# TLSR826X register map
File version: 0.1
Auto-generated SVD for Telink TLSR826X
Registers are 8-bit, access not given, no defined reset value unless marked. A register's access mark holds for its fields unless they carry their own. Offsets are from the block's base; lines under a group give offsets from that group; [hi:lo] are bit positions; {n}, {i} and the like mark numbered series; 'fields as' and 'values as' point back to an identical list; <NAME> marks a mode.

## Memory map
0x00800000 SECONDARY_I2C — Auto-generated from section 'secondary i2c'
0x00800008 SECONDARY_SPI — Auto-generated from section 'secondary spi'
0x0080000C MASTER_SPI — Auto-generated from section 'master spi'
0x00800010 OTP — Auto-generated from section 'otp'
0x00800028 ADC — Auto-generated from section 'adc'
0x00800056 AUDIO — Auto-generated from section 'audio'
0x00800060 SYS — Auto-generated from section 'sys'
0x00800074 DEV_ID — Auto-generated from section 'dev_id'
0x00800080 MAC — Auto-generated from section 'mac'
0x008000B0 SWIRE — Auto-generated from section 'swire'
0x00800500 DMA_MAC — Auto-generated from section 'dma mac'
0x00800580 GPIO — Auto-generated from section 'gpio'
0x00800620 TIMER — Auto-generated from section 'timer'
0x00800640 INTERRUPT — Auto-generated from section 'interrupt'
0x00800780 PWM — Auto-generated from section 'PWM'
0x00800B00 DFIFO — Auto-generated from section 'dfifo'

## SECONDARY_I2C — Auto-generated from section 'secondary i2c'
Base 0x00800000
0x00 I2C_SET 32-bit — Auto-generated from i2c_set; aliases: I2C_SPEED
0x01 I2C_ID — Auto-generated from i2c_id
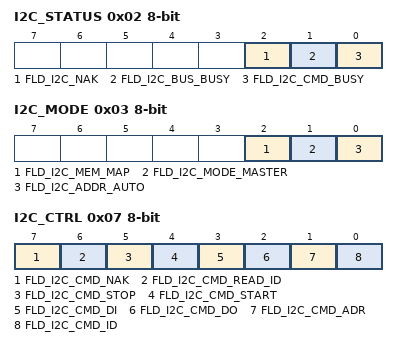
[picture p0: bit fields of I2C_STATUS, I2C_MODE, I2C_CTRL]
0x02 I2C_STATUS — Auto-generated from i2c_status
  [2] FLD_I2C_NAK, [1] FLD_I2C_BUS_BUSY, [0] FLD_I2C_CMD_BUSY
0x03 I2C_MODE — Auto-generated from i2c_mode
  [2] FLD_I2C_MEM_MAP, [1] FLD_I2C_MODE_MASTER, [0] FLD_I2C_ADDR_AUTO
0x04 I2C_ADR_DAT 32-bit — Auto-generated from i2c_adr_dat; aliases: I2C_ADR, I2C_DAT_CTRL
0x05 I2C_DO — Auto-generated from i2c_do
0x06 I2C_DI_CTRL 16-bit — Auto-generated from i2c_di_ctrl; aliases: I2C_DI
0x07 I2C_CTRL — Auto-generated from i2c_ctrl
  [7] FLD_I2C_CMD_NAK, [6] FLD_I2C_CMD_READ_ID, [5] FLD_I2C_CMD_STOP, [4] FLD_I2C_CMD_START, [3] FLD_I2C_CMD_DI, [2] FLD_I2C_CMD_DO, [1] FLD_I2C_CMD_ADR, [0] FLD_I2C_CMD_ID

## SECONDARY_SPI — Auto-generated from section 'secondary spi'
Base 0x00800008
0x00 SPI_DATA — Auto-generated from spi_data
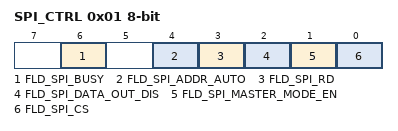
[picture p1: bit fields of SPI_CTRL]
0x01 SPI_CTRL — Auto-generated from spi_ctrl
  [6] FLD_SPI_BUSY, [4] FLD_SPI_ADDR_AUTO, [3] FLD_SPI_RD, [2] FLD_SPI_DATA_OUT_DIS, [1] FLD_SPI_MASTER_MODE_EN, [0] FLD_SPI_CS
0x02 SPI_SP — Auto-generated from spi_sp
  [7] FLD_SPI_ENABLE, [7] FLD_SPI_PAD_SEL, [6:0] FLD_MASTER_SPI_CLK
0x03 SPI_INV_CLK — Auto-generated from spi_inv_clk

## MASTER_SPI — Auto-generated from section 'master spi'
Base 0x0080000C
0x00 MASTER_SPI_DATA — Auto-generated from master_spi_data
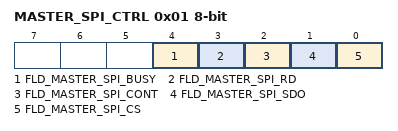
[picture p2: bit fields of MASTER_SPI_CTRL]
0x01 MASTER_SPI_CTRL — Auto-generated from master_spi_ctrl
  [4] FLD_MASTER_SPI_BUSY, [3] FLD_MASTER_SPI_RD, [2] FLD_MASTER_SPI_CONT, [1] FLD_MASTER_SPI_SDO, [0] FLD_MASTER_SPI_CS

## OTP — Auto-generated from section 'otp'
Base 0x00800010
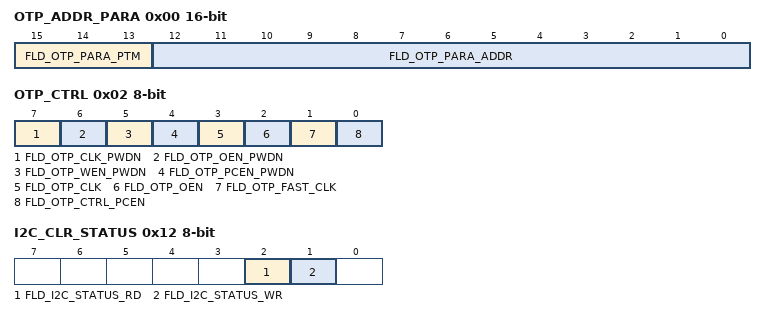
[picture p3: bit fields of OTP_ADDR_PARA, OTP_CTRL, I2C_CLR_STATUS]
0x00 OTP_ADDR_PARA 16-bit — Auto-generated from otp_addr_para
  [15:13] FLD_OTP_PARA_PTM, [12:0] FLD_OTP_PARA_ADDR
0x02 OTP_CTRL — Auto-generated from otp_ctrl
  [7] FLD_OTP_CLK_PWDN, [6] FLD_OTP_OEN_PWDN, [5] FLD_OTP_WEN_PWDN, [4] FLD_OTP_PCEN_PWDN, [3] FLD_OTP_CLK, [2] FLD_OTP_OEN, [1] FLD_OTP_FAST_CLK, [0] FLD_OTP_CTRL_PCEN
0x03 OTP_BYTE_DAT — Auto-generated from otp_byte_dat
0x04 OTP_DAT 32-bit — Auto-generated from otp_dat
0x08 OTP_BLK_CODE — Auto-generated from otp_blk_code
0x11 I2C_IRQ_STATUS — Auto-generated from i2c_irq_status
0x12 I2C_CLR_STATUS — Auto-generated from i2c_clr_status
  [2] FLD_I2C_STATUS_RD, [1] FLD_I2C_STATUS_WR

## ADC — Auto-generated from section 'adc'
Base 0x00800028
0x00 ADC_PGA_SEL_M — Auto-generated from adc_pga_sel_m
0x01 ADC_PGA_SEL_L — Auto-generated from adc_pga_sel_l
0x02 ADC_PGA_SEL_R — Auto-generated from adc_pga_sel_r
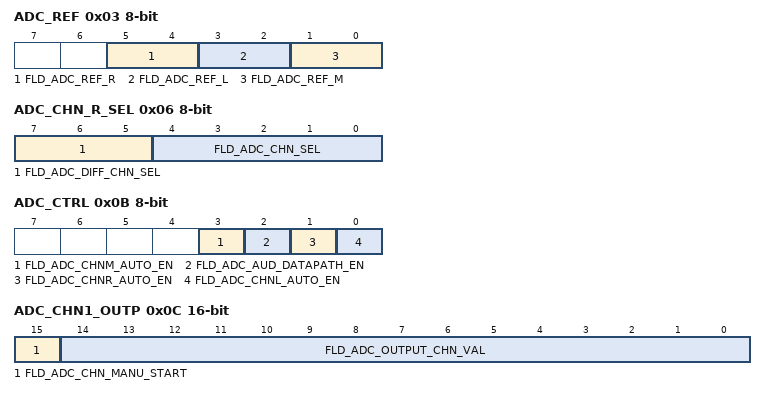
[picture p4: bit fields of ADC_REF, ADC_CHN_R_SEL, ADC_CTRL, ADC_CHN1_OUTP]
0x03 ADC_REF — Auto-generated from adc_ref; aliases: ADC_REF
  [5:4] FLD_ADC_REF_R, [3:2] FLD_ADC_REF_L, [1:0] FLD_ADC_REF_M
0x04 ADC_CHN_M_SEL — Auto-generated from adc_chn_m_sel
0x05 ADC_CHN_L_SEL — Auto-generated from adc_chn_l_sel
0x06 ADC_CHN_R_SEL — Auto-generated from adc_chn_r_sel
  [7:5] FLD_ADC_DIFF_CHN_SEL, [4:0] FLD_ADC_CHN_SEL
0x07 ADC_RES_LR — Auto-generated from adc_res_lr
0x08 ADC_PERIOD_CHN0 16-bit — Auto-generated from adc_period_chn0
0x0A ADC_PERIOD_CHN12 — Auto-generated from adc_period_chn12
0x0B ADC_CTRL — Auto-generated from adc_ctrl
  [3] FLD_ADC_CHNM_AUTO_EN, [2] FLD_ADC_AUD_DATAPATH_EN, [1] FLD_ADC_CHNR_AUTO_EN, [0] FLD_ADC_CHNL_AUTO_EN
0x0C ADC_CHN1_OUTP 16-bit — Auto-generated from adc_chn1_outp
  [15] FLD_ADC_CHN_MANU_START, [14:0] FLD_ADC_OUTPUT_CHN_VAL
0x0E ADC_CHN2_OUTP 16-bit — Auto-generated from adc_chn2_outp
0x10 ADC_DAT_BYP_OUTP 16-bit — Auto-generated from adc_dat_byp_outp
0x12 ADC_CHN0_INPUT 16-bit — Auto-generated from adc_chn0_input
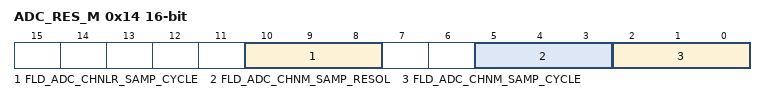
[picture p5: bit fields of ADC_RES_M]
0x14 ADC_RES_M 16-bit — Auto-generated from adc_res_m; aliases: ADC_SAMP_RES
  [10:8] FLD_ADC_CHNLR_SAMP_CYCLE, [5:3] FLD_ADC_CHNM_SAMP_RESOL, [2:0] FLD_ADC_CHNM_SAMP_CYCLE
0x15 ADC_TSAMP_LR — Auto-generated from adc_tsamp_lr
